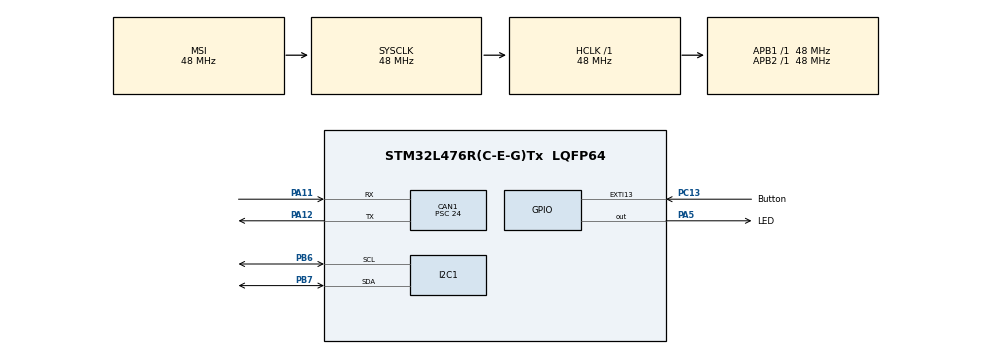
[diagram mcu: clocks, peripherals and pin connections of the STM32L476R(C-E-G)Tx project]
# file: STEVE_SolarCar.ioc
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CAN1.BS1=CAN_BS1_13TQ
CAN1.BS2=CAN_BS2_2TQ
CAN1.CalculateTimeBit=8000
CAN1.CalculateTimeQuantum=500.0
CAN1.Prescaler=24
I2C1.OwnAddress2Masks=I2C_OA2_NOMASK
I2C1.Timing=0x20303E5D
Mcu.Family=STM32L4
Mcu.Name=STM32L476R(C-E-G)Tx
Mcu.Package=LQFP64
NVIC.EXTI15_10_IRQn=true\:0\:0\:false\:false\:true
NVIC.PriorityGroup=NVIC_PRIORITYGROUP_4
NVIC.TIM6_DAC_IRQn=true\:0\:0\:true\:false\:true
PA11.Mode=Master
PA11.Signal=CAN1_RX
PA12.Mode=Master
PA12.Signal=CAN1_TX
PA5.GPIO_Label=LED
PA5.Signal=GPIO_Output
PB6.Mode=I2C
PB6.Signal=I2C1_SCL
PB7.Mode=I2C
PB7.Signal=I2C1_SDA
PC13.GPIO_Label=Button
PC13.GPIO_ModeDefaultEXTI=GPIO_MODE_IT_FALLING
PC13.Signal=GPXTI13
ProjectManager.HeapSize=0x200
ProjectManager.StackSize=0x400
ProjectManager.TargetToolchain=TrueSTUDIO
RCC.ADCFreq_Value=192000000
RCC.AHBCLKDivider=RCC_SYSCLK_DIV1
RCC.AHBFreq_Value=48000000
RCC.APB1Freq_Value=48000000
RCC.APB1TimFreq_Value=48000000
RCC.APB2Freq_Value=48000000
RCC.APB2TimFreq_Value=48000000
RCC.ClockTypeHCLK=RCC_CLOCKTYPE_HCLK
RCC.ClockTypePCLK1=RCC_CLOCKTYPE_PCLK1
RCC.ClockTypePCLK2=RCC_CLOCKTYPE_PCLK2
RCC.ClockTypeSysClk=RCC_CLOCKTYPE_SYSCLK
RCC.CortexFreq_Value=48000000
RCC.EnableCSSLSE=false
RCC.EnbaleCSS=false
RCC.HCLKFreq_Value=48000000
RCC.HSE_VALUE=8000000
RCC.HSI_VALUE=16000000
RCC.LSE_VALUE=32768
RCC.MSIClockRange=RCC_MSIRANGE_11
RCC.MSI_VALUE=48000000
RCC.SYSCLKFreq_VALUE=48000000
RCC.USBFreq_Value=192000000
RCC.VCOOutputFreq_Value=384000000
TIM6.Period=100
TIM6.Prescaler=4800
TIM6.TIM_MasterSlaveMode=TIM_MASTERSLAVEMODE_DISABLE
VP_TIM6_VS_ClockSourceINT.Mode=Enable_Timer
board=STEVE_SolarCar

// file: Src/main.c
/**
  ******************************************************************************
  * File Name          : main.c
  * Description        : Main program body
  ******************************************************************************
  *
  * COPYRIGHT(c) 2017 STMicroelectronics
  *
  * Redistribution and use in source and binary forms, with or without modification,
  * are permitted provided that the following conditions are met:
  *   1. Redistributions of source code must retain the above copyright notice,
  *      this list of conditions and the following disclaimer.
  *   2. Redistributions in binary form must reproduce the above copyright notice,
  *      this list of conditions and the following disclaimer in the documentation
  *      and/or other materials provided with the distribution.
  *   3. Neither the name of STMicroelectronics nor the names of its contributors
  *      may be used to endorse or promote products derived from this software
  *      without specific prior written permission.
  *
  * THIS SOFTWARE IS PROVIDED BY THE COPYRIGHT HOLDERS AND CONTRIBUTORS "AS IS"
  * AND ANY EXPRESS OR IMPLIED WARRANTIES, INCLUDING, BUT NOT LIMITED TO, THE
  * IMPLIED WARRANTIES OF MERCHANTABILITY AND FITNESS FOR A PARTICULAR PURPOSE ARE
  * DISCLAIMED. IN NO EVENT SHALL THE COPYRIGHT HOLDER OR CONTRIBUTORS BE LIABLE
  * FOR ANY DIRECT, INDIRECT, INCIDENTAL, SPECIAL, EXEMPLARY, OR CONSEQUENTIAL
  * DAMAGES (INCLUDING, BUT NOT LIMITED TO, PROCUREMENT OF SUBSTITUTE GOODS OR
  * SERVICES; LOSS OF USE, DATA, OR PROFITS; OR BUSINESS INTERRUPTION) HOWEVER
  * CAUSED AND ON ANY THEORY OF LIABILITY, WHETHER IN CONTRACT, STRICT LIABILITY,
  * OR TORT (INCLUDING NEGLIGENCE OR OTHERWISE) ARISING IN ANY WAY OUT OF THE USE
  * OF THIS SOFTWARE, EVEN IF ADVISED OF THE POSSIBILITY OF SUCH DAMAGE.
  *
  ******************************************************************************
  */
#include "main.h"
#include "stm32l4xx_hal.h"

/* USER CODE BEGIN Includes */
#include "dataStructs.h"
#include "buttonHandler.h"
#include "Tests.h"

/* USER CODE END Includes */

CAN_HandleTypeDef hcan1;

I2C_HandleTypeDef hi2c1;

TIM_HandleTypeDef htim6;

/* USER CODE BEGIN PV */
/* Private variables ---------------------------------------------------------*/

/* USER CODE END PV */

void SystemClock_Config(void);
void Error_Handler(void);
static void MX_GPIO_Init(void);
static void MX_CAN1_Init(void);
static void MX_I2C1_Init(void);
static void MX_TIM6_Init(void);

/* USER CODE BEGIN PFP */
/* Private function prototypes -----------------------------------------------*/

/* USER CODE END PFP */

int main(void)
{

  /* USER CODE BEGIN 1 */
	//uint32_t currentTime = time();

  /* USER CODE END 1 */

  /* MCU Configuration----------------------------------------------------------*/

  /* Reset of all peripherals, Initializes the Flash interface and the Systick. */
  HAL_Init();

  /* Configure the system clock */
  SystemClock_Config();

  /* Initialize all configured peripherals */
  MX_GPIO_Init();
  MX_CAN1_Init();
  MX_I2C1_Init();
  MX_TIM6_Init();

  /* USER CODE BEGIN 2 */

  HAL_TIM_Base_Start_IT(&htim6);

  /* Tests Start*/

  char testResult = testCANdataConv();

  /* Tests End */

  /* USER CODE END 2 */

  /* Infinite loop */
  while (1)
  {

  /* USER CODE BEGIN 3 */

	  buttonEventHandler();

  }
  /* USER CODE END 3 */

}

/** System Clock Configuration
*/
void SystemClock_Config(void)
{

  RCC_OscInitTypeDef RCC_OscInitStruct;
  RCC_ClkInitTypeDef RCC_ClkInitStruct;
  RCC_PeriphCLKInitTypeDef PeriphClkInit;

    /**Initializes the CPU, AHB and APB busses clocks
    */
  RCC_OscInitStruct.OscillatorType = RCC_OSCILLATORTYPE_MSI;
  RCC_OscInitStruct.MSIState = RCC_MSI_ON;
  RCC_OscInitStruct.MSICalibrationValue = 0;
  RCC_OscInitStruct.MSIClockRange = RCC_MSIRANGE_11;
  RCC_OscInitStruct.PLL.PLLState = RCC_PLL_NONE;
  if (HAL_RCC_OscConfig(&RCC_OscInitStruct) != HAL_OK)
  {
    Error_Handler();
  }

    /**Initializes the CPU, AHB and APB busses clocks
    */
  RCC_ClkInitStruct.ClockType = RCC_CLOCKTYPE_HCLK|RCC_CLOCKTYPE_SYSCLK
                              |RCC_CLOCKTYPE_PCLK1|RCC_CLOCKTYPE_PCLK2;
  RCC_ClkInitStruct.SYSCLKSource = RCC_SYSCLKSOURCE_MSI;
  RCC_ClkInitStruct.AHBCLKDivider = RCC_SYSCLK_DIV1;
  RCC_ClkInitStruct.APB1CLKDivider = RCC_HCLK_DIV1;
  RCC_ClkInitStruct.APB2CLKDivider = RCC_HCLK_DIV1;

  if (HAL_RCC_ClockConfig(&RCC_ClkInitStruct, FLASH_LATENCY_2) != HAL_OK)
  {
    Error_Handler();
  }

  PeriphClkInit.PeriphClockSelection = RCC_PERIPHCLK_I2C1;
  PeriphClkInit.I2c1ClockSelection = RCC_I2C1CLKSOURCE_PCLK1;
  if (HAL_RCCEx_PeriphCLKConfig(&PeriphClkInit) != HAL_OK)
  {
    Error_Handler();
  }

    /**Configure the main internal regulator output voltage
    */
  if (HAL_PWREx_ControlVoltageScaling(PWR_REGULATOR_VOLTAGE_SCALE1) != HAL_OK)
  {
    Error_Handler();
  }

    /**Configure the Systick interrupt time
    */
  HAL_SYSTICK_Config(HAL_RCC_GetHCLKFreq()/1000);

    /**Configure the Systick
    */
  HAL_SYSTICK_CLKSourceConfig(SYSTICK_CLKSOURCE_HCLK);

  /* SysTick_IRQn interrupt configuration */
  HAL_NVIC_SetPriority(SysTick_IRQn, 0, 0);
}

/* CAN1 init function */
static void MX_CAN1_Init(void)
{

  hcan1.Instance = CAN1;
  hcan1.Init.Prescaler = 24;
  hcan1.Init.Mode = CAN_MODE_NORMAL;
  hcan1.Init.SJW = CAN_SJW_1TQ;
  hcan1.Init.BS1 = CAN_BS1_13TQ;
  hcan1.Init.BS2 = CAN_BS2_2TQ;
  hcan1.Init.TTCM = DISABLE;
  hcan1.Init.ABOM = DISABLE;
  hcan1.Init.AWUM = DISABLE;
  hcan1.Init.NART = DISABLE;
  hcan1.Init.RFLM = DISABLE;
  hcan1.Init.TXFP = DISABLE;
  if (HAL_CAN_Init(&hcan1) != HAL_OK)
  {
    Error_Handler();
  }

}

/* I2C1 init function */
static void MX_I2C1_Init(void)
{

  hi2c1.Instance = I2C1;
  hi2c1.Init.Timing = 0x20303E5D;
  hi2c1.Init.OwnAddress1 = 0;
  hi2c1.Init.AddressingMode = I2C_ADDRESSINGMODE_7BIT;
  hi2c1.Init.DualAddressMode = I2C_DUALADDRESS_DISABLE;
  hi2c1.Init.OwnAddress2 = 0;
  hi2c1.Init.OwnAddress2Masks = I2C_OA2_NOMASK;
  hi2c1.Init.GeneralCallMode = I2C_GENERALCALL_DISABLE;
  hi2c1.Init.NoStretchMode = I2C_NOSTRETCH_DISABLE;
  if (HAL_I2C_Init(&hi2c1) != HAL_OK)
  {
    Error_Handler();
  }

    /**Configure Analogue filter
    */
  if (HAL_I2CEx_ConfigAnalogFilter(&hi2c1, I2C_ANALOGFILTER_ENABLE) != HAL_OK)
  {
    Error_Handler();
  }

    /**Configure Digital filter
    */
  if (HAL_I2CEx_ConfigDigitalFilter(&hi2c1, 0) != HAL_OK)
  {
    Error_Handler();
  }

}

/* TIM6 init function */
static void MX_TIM6_Init(void)
{

  TIM_MasterConfigTypeDef sMasterConfig;

  htim6.Instance = TIM6;
  htim6.Init.Prescaler = 4800;
  htim6.Init.CounterMode = TIM_COUNTERMODE_UP;
  htim6.Init.Period = 100;
  if (HAL_TIM_Base_Init(&htim6) != HAL_OK)
  {
    Error_Handler();
  }

  sMasterConfig.MasterOutputTrigger = TIM_TRGO_RESET;
  sMasterConfig.MasterSlaveMode = TIM_MASTERSLAVEMODE_DISABLE;
  if (HAL_TIMEx_MasterConfigSynchronization(&htim6, &sMasterConfig) != HAL_OK)
  {
    Error_Handler();
  }

}

/** Configure pins as
        * Analog
        * Input
        * Output
        * EVENT_OUT
        * EXTI
*/
static void MX_GPIO_Init(void)
{

  GPIO_InitTypeDef GPIO_InitStruct;

  /* GPIO Ports Clock Enable */
  __HAL_RCC_GPIOC_CLK_ENABLE();
  __HAL_RCC_GPIOA_CLK_ENABLE();
  __HAL_RCC_GPIOB_CLK_ENABLE();

  /*Configure GPIO pin Output Level */
  HAL_GPIO_WritePin(LED_GPIO_Port, LED_Pin, GPIO_PIN_RESET);

  /*Configure GPIO pin : Button_Pin */
  GPIO_InitStruct.Pin = Button_Pin;
  GPIO_InitStruct.Mode = GPIO_MODE_IT_FALLING;
  GPIO_InitStruct.Pull = GPIO_NOPULL;
  HAL_GPIO_Init(Button_GPIO_Port, &GPIO_InitStruct);

  /*Configure GPIO pin : LED_Pin */
  GPIO_InitStruct.Pin = LED_Pin;
  GPIO_InitStruct.Mode = GPIO_MODE_OUTPUT_PP;
  GPIO_InitStruct.Pull = GPIO_NOPULL;
  GPIO_InitStruct.Speed = GPIO_SPEED_FREQ_LOW;
  HAL_GPIO_Init(LED_GPIO_Port, &GPIO_InitStruct);

  /* EXTI interrupt init*/
  HAL_NVIC_SetPriority(EXTI15_10_IRQn, 0, 0);
  HAL_NVIC_EnableIRQ(EXTI15_10_IRQn);

}

void Error_Handler(void)
{
  while(1)
  {
  }
}

/************************ (C) COPYRIGHT STMicroelectronics *****END OF FILE****/
